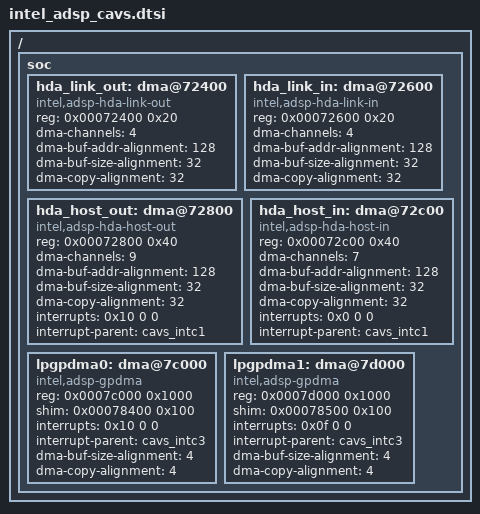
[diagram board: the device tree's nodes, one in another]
/*
 * Copyright (c) 2022 Intel Corporation
 *
 * SPDX-License-Identifier: Apache-2.0
 */

#include <xtensa/xtensa.dtsi>

/ {
	soc {
		hda_link_out: dma@72400 {
			compatible = "intel,adsp-hda-link-out";
			reg = <0x00072400 0x20>;
			#dma-cells = <1>;
			dma-channels = <4>;
			dma-buf-addr-alignment = <128>;
			dma-buf-size-alignment = <32>;
			dma-copy-alignment = <32>;

			status = "okay";
		};

		hda_link_in: dma@72600 {
			compatible = "intel,adsp-hda-link-in";
			reg = <0x00072600 0x20>;
			#dma-cells = <1>;
			dma-channels = <4>;
			dma-buf-addr-alignment = <128>;
			dma-buf-size-alignment = <32>;
			dma-copy-alignment = <32>;

			status = "okay";
		};

		hda_host_out: dma@72800 {
			compatible = "intel,adsp-hda-host-out";
			reg = <0x00072800 0x40>;
			#dma-cells = <1>;
			dma-channels = <9>;
			dma-buf-addr-alignment = <128>;
			dma-buf-size-alignment = <32>;
			dma-copy-alignment = <32>;
			interrupts = <0x10 0 0>;
			interrupt-parent = <&cavs_intc1>;
			status = "okay";
		};

		hda_host_in: dma@72c00 {
			compatible = "intel,adsp-hda-host-in";
			reg = <0x00072c00 0x40>;
			#dma-cells = <1>;
			dma-channels = <7>;
			dma-buf-addr-alignment = <128>;
			dma-buf-size-alignment = <32>;
			dma-copy-alignment = <32>;
			interrupts = <0x0 0 0>;
			interrupt-parent = <&cavs_intc1>;
			status = "okay";
		};

		lpgpdma0: dma@7c000 {
			compatible = "intel,adsp-gpdma";
			reg = <0x0007c000 0x1000>;
			#dma-cells = <1>;
			shim = <0x00078400 0x100>;
			interrupts = <0x10 0 0>;
			interrupt-parent = <&cavs_intc3>;
			dma-buf-size-alignment = <4>;
			dma-copy-alignment = <4>;

			status = "okay";
		};

		lpgpdma1: dma@7d000 {
			compatible = "intel,adsp-gpdma";
			reg = <0x0007d000 0x1000>;
			#dma-cells = <1>;
			shim = <0x00078500 0x100>;
			interrupts = <0x0f 0 0>;
			interrupt-parent = <&cavs_intc3>;
			dma-buf-size-alignment = <4>;
			dma-copy-alignment = <4>;

			status = "okay";
		};
	};
};
